# pdsp register map
Vendor: Texas Instruments
Peripheral module from a debugger description file (folder pdsp).
Registers are 32-bit, read-write, no defined reset value unless marked. A register's access mark holds for its fields unless they carry their own. Offsets are as the file gives them; lines under a group give offsets from that group; [hi:lo] are bit positions; {n}, {i} and the like mark numbered series; 'fields as' and 'values as' point back to an identical list; <NAME> marks a mode.

## QMSS_8_PDSP
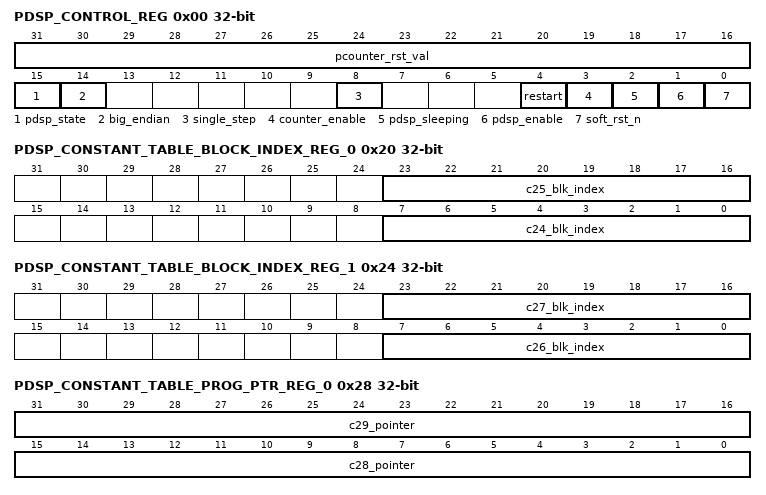
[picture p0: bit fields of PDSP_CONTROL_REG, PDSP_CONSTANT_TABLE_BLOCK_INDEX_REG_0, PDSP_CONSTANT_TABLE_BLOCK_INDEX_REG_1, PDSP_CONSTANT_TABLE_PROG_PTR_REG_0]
0x00 PDSP_CONTROL_REG access per field — (1 of 1, stride 0)
  [31:16] pcounter_rst_val rw — Program counter reset value
  [15] pdsp_state ro — PDSP run state: 0=PDSP is halted, 1=PDSP is running
  [14] big_endian ro — Big-endian input state
  [8] single_step rw — Single step enable: 0=PDSP will free run when enabled, 1=PDSP will execute a single instruction and then the pdsp_enable bit will be cleared
  [4] restart rw — Causes PDSP to stop current operation gracefully and return to the PC reset value
  [3] counter_enable rw — PDSP cycle counter enable: 0=Counters not enabled, 1=Counters enabled
  [2] pdsp_sleeping rw — PDSP sleep indicator: 0=PDSP is not asleep, 1=PDSP us asleep
  [1] pdsp_enable rw — PDSP enable: 0=PDSP is disabled, 1=PDSP is enabled
  [0] soft_rst_n ro — Soft reset. When this bit is cleared, the PDSP will be reset. This bit is set back to 1 on the next cycle after it has been cleared.
0x04 PDSP_STATUS_REG ro — (1 of 1, stride 0)
  [15:0] pcounter — Current PDSP program counter
0x08 PDSP_WAKEUP_ENABLE_REG — (1 of 1, stride 0)
  [31:0] bitwise_enables — Wakeup enables
0x0C PDSP_CYCLE_COUNT_REG — (1 of 1, stride 0)
  [31:0] cyclecount — This value is incremented by 1 for every clock cycle during which the PDSP is enabled and the counter is enabled.
0x10 PDSP_STALL_COUNT_REG ro — (1 of 1, stride 0)
  [31:0] stallcount — This value is incremented by 1 for every clock cycle during which the PDSP is enabled, the counter is enabled, and the PDSP was unable to fetch a new instruction for any reason.
0x20 PDSP_CONSTANT_TABLE_BLOCK_INDEX_REG_0 — (1 of 1, stride 0)
  [23:16] c25_blk_index — PDSP constant entry 25 block index
  [7:0] c24_blk_index — PDSP constant entry 24 block index
0x24 PDSP_CONSTANT_TABLE_BLOCK_INDEX_REG_1 — (1 of 1, stride 0)
  [23:16] c27_blk_index — PDSP constant entry 27 block index
  [7:0] c26_blk_index — PDSP constant entry 26 block index
0x28 PDSP_CONSTANT_TABLE_PROG_PTR_REG_0 — (1 of 1, stride 0)
  [31:16] c29_pointer — PDSP constant entry 29 pointer
  [15:0] c28_pointer — PDSP constant entry 28 pointer
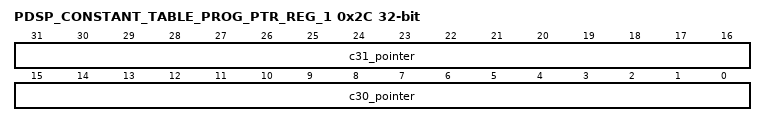
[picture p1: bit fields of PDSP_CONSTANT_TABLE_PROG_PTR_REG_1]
0x2C PDSP_CONSTANT_TABLE_PROG_PTR_REG_1 — (1 of 1, stride 0)
  [31:16] c31_pointer — PDSP constant entry 31 pointer
  [15:0] c30_pointer — PDSP constant entry 30 pointer
0x800 PDSP_IGP — (1 of 1, stride 0)
  [31:0] regN — PDSP Internal GP Register N
0x880 PDSP_ICTE ro — (1 of 1, stride 0)
  [31:0] ct_entryN — PDSP Internal Constants Table Entry N
0x1000 PDSP_Instruction_RAM — (1 of 2048, stride 4)
  [31:0] PDSP_IRAM
